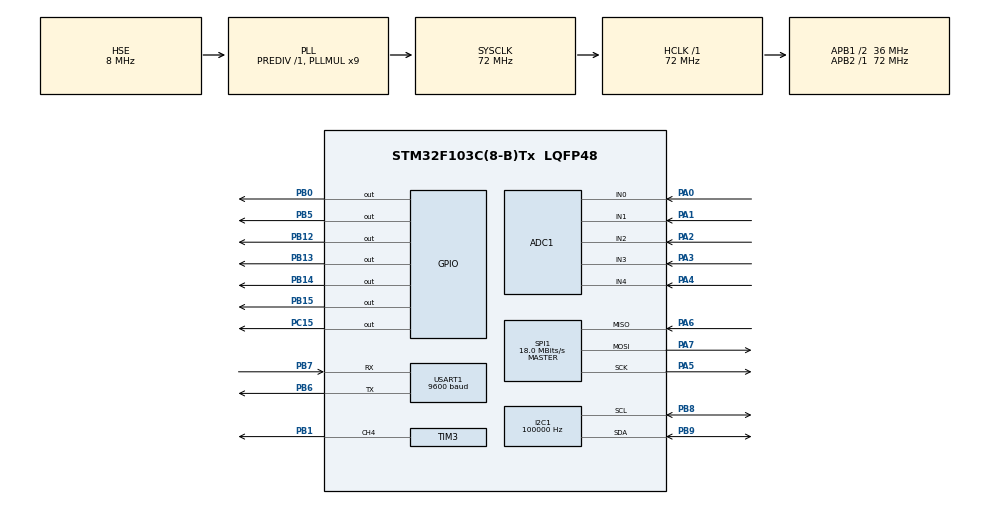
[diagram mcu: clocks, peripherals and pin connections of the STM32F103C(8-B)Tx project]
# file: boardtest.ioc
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ADC1.Channel-12\#ChannelRegularConversion=ADC_CHANNEL_0
ADC1.Channel-13\#ChannelRegularConversion=ADC_CHANNEL_1
ADC1.Channel-14\#ChannelRegularConversion=ADC_CHANNEL_2
ADC1.Channel-15\#ChannelRegularConversion=ADC_CHANNEL_3
ADC1.Channel-16\#ChannelRegularConversion=ADC_CHANNEL_4
ADC1.ContinuousConvMode=ENABLE
ADC1.NbrOfConversion=5
ADC1.NbrOfConversionFlag=1
ADC1.Rank-12\#ChannelRegularConversion=1
ADC1.Rank-13\#ChannelRegularConversion=2
ADC1.Rank-14\#ChannelRegularConversion=3
ADC1.Rank-15\#ChannelRegularConversion=4
ADC1.Rank-16\#ChannelRegularConversion=5
ADC1.SamplingTime-12\#ChannelRegularConversion=ADC_SAMPLETIME_239CYCLES_5
ADC1.SamplingTime-13\#ChannelRegularConversion=ADC_SAMPLETIME_239CYCLES_5
ADC1.SamplingTime-14\#ChannelRegularConversion=ADC_SAMPLETIME_239CYCLES_5
ADC1.SamplingTime-15\#ChannelRegularConversion=ADC_SAMPLETIME_239CYCLES_5
ADC1.SamplingTime-16\#ChannelRegularConversion=ADC_SAMPLETIME_239CYCLES_5
ADC1.master=1
Dma.ADC1.0.Direction=DMA_PERIPH_TO_MEMORY
Dma.ADC1.0.Instance=DMA1_Channel1
Dma.ADC1.0.MemDataAlignment=DMA_MDATAALIGN_HALFWORD
Dma.ADC1.0.MemInc=DMA_MINC_ENABLE
Dma.ADC1.0.Mode=DMA_CIRCULAR
Dma.ADC1.0.PeriphDataAlignment=DMA_PDATAALIGN_HALFWORD
Dma.ADC1.0.PeriphInc=DMA_PINC_DISABLE
Dma.ADC1.0.Priority=DMA_PRIORITY_HIGH
Dma.Request0=ADC1
Dma.Request1=USART1_TX
Dma.USART1_TX.1.Direction=DMA_MEMORY_TO_PERIPH
Dma.USART1_TX.1.Instance=DMA1_Channel4
Dma.USART1_TX.1.MemDataAlignment=DMA_MDATAALIGN_BYTE
Dma.USART1_TX.1.MemInc=DMA_MINC_ENABLE
Dma.USART1_TX.1.Mode=DMA_CIRCULAR
Dma.USART1_TX.1.PeriphDataAlignment=DMA_PDATAALIGN_BYTE
Dma.USART1_TX.1.PeriphInc=DMA_PINC_DISABLE
Dma.USART1_TX.1.Priority=DMA_PRIORITY_MEDIUM
FREERTOS.Tasks01=defaultTask,0,128,StartDefaultTask,Default,NULL,Dynamic,NULL,NULL;myTask_led,-3,128,Task_led,As weak,NULL,Dynamic,NULL,NULL;Task_buzzer,-3,128,myTask_buzzer,As weak,NULL,Dynamic,NULL,NULL;myTask_Date_pac,-3,128,Task_Date_pack,As weak,NULL,Dynamic,NULL,NULL;myTask_adc,-3,128,Task_adc,As weak,NULL,Dynamic,NULL,NULL;myTask_ic_rgb,-3,128,Task_ic_rgb,As weak,NULL,Dynamic,NULL,NULL;myTask_oled_gui,-3,128,Task_oled_gui,As weak,NULL,Dynamic,NULL,NULL;myTask_key,-3,128,Task_key,As weak,NULL,Dynamic,NULL,NULL
FREERTOS.configTOTAL_HEAP_SIZE=10000
I2C1.ClockSpeed=100000
I2C1.I2C_Mode=I2C_Fast
Mcu.Family=STM32F1
Mcu.Name=STM32F103C(8-B)Tx
Mcu.Package=LQFP48
NVIC.DMA1_Channel1_IRQn=true\:5\:0\:false\:false\:true\:true\:false\:true\:true
NVIC.DMA1_Channel4_IRQn=true\:5\:0\:false\:false\:true\:true\:false\:true\:true
NVIC.PriorityGroup=NVIC_PRIORITYGROUP_4
NVIC.USART1_IRQn=true\:5\:0\:false\:false\:true\:true\:true\:true\:true
PA0-WKUP.Signal=ADCx_IN0
PA1.Signal=ADCx_IN1
PA13.Mode=Serial_Wire
PA13.Signal=SYS_JTMS-SWDIO
PA14.Mode=Serial_Wire
PA14.Signal=SYS_JTCK-SWCLK
PA2.Signal=ADCx_IN2
PA3.Signal=ADCx_IN3
PA4.Signal=ADCx_IN4
PA5.Mode=Full_Duplex_Master
PA5.Signal=SPI1_SCK
PA6.Mode=Full_Duplex_Master
PA6.Signal=SPI1_MISO
PA7.Mode=Full_Duplex_Master
PA7.Signal=SPI1_MOSI
PB0.GPIO_Speed=GPIO_SPEED_FREQ_HIGH
PB0.Signal=GPIO_Output
PB1.Signal=S_TIM3_CH4
PB12.Signal=GPIO_Output
PB13.Signal=GPIO_Output
PB14.Signal=GPIO_Output
PB15.Signal=GPIO_Output
PB5.Signal=GPIO_Output
PB6.Mode=Asynchronous
PB6.Signal=USART1_TX
PB7.Mode=Asynchronous
PB7.Signal=USART1_RX
PB8.Mode=I2C
PB8.Signal=I2C1_SCL
PB9.Mode=I2C
PB9.Signal=I2C1_SDA
PC15-OSC32_OUT.GPIO_Speed=GPIO_SPEED_FREQ_HIGH
PC15-OSC32_OUT.Signal=GPIO_Output
PD0-OSC_IN.Mode=HSE-External-Oscillator
PD0-OSC_IN.Signal=RCC_OSC_IN
PD1-OSC_OUT.Mode=HSE-External-Oscillator
PD1-OSC_OUT.Signal=RCC_OSC_OUT
ProjectManager.HeapSize=0x200
ProjectManager.StackSize=0x400
ProjectManager.TargetToolchain=MDK-ARM V5.32
RCC.ADCPresc=RCC_ADCPCLK2_DIV6
RCC.AHBFreq_Value=72000000
RCC.APB1CLKDivider=RCC_HCLK_DIV2
RCC.APB1Freq_Value=36000000
RCC.APB1TimFreq_Value=72000000
RCC.APB2Freq_Value=72000000
RCC.APB2TimFreq_Value=72000000
RCC.HCLKFreq_Value=72000000
RCC.PLLMUL=RCC_PLL_MUL9
RCC.PLLSourceVirtual=RCC_PLLSOURCE_HSE
RCC.SYSCLKFreq_VALUE=72000000
RCC.SYSCLKSource=RCC_SYSCLKSOURCE_PLLCLK
RCC.USBFreq_Value=72000000
SH.ADCx_IN0.0=ADC1_IN0,IN0
SH.ADCx_IN1.0=ADC1_IN1,IN1
SH.ADCx_IN2.0=ADC1_IN2,IN2
SH.ADCx_IN3.0=ADC1_IN3,IN3
SH.ADCx_IN4.0=ADC1_IN4,IN4
SH.S_TIM3_CH4.0=TIM3_CH4,PWM Generation4 CH4
SPI1.BaudRatePrescaler=SPI_BAUDRATEPRESCALER_4
SPI1.CalculateBaudRate=18.0 MBits/s
SPI1.Direction=SPI_DIRECTION_2LINES
SPI1.Mode=SPI_MODE_MASTER
SPI1.VirtualType=VM_MASTER
TIM3.Channel-PWM\ Generation4\ CH4=TIM_CHANNEL_4
TIM3.Period=999
TIM3.Prescaler=1
TIM3.Pulse-PWM\ Generation4\ CH4=500
USART1.BaudRate=9600
USART1.VirtualMode=VM_ASYNC
VP_FREERTOS_VS_CMSIS_V1.Mode=CMSIS_V1
VP_TIM3_VS_ClockSourceINT.Mode=Internal
board=custom

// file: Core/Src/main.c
/* USER CODE BEGIN Header */
/**
  ******************************************************************************
  * @file           : main.c
  * @brief          : Main program body
  ******************************************************************************
  * @attention
  *
  * Copyright (c) 2023 STMicroelectronics.
  * All rights reserved.
  *
  * This software is licensed under terms that can be found in the LICENSE file
  * in the root directory of this software component.
  * If no LICENSE file comes with this software, it is provided AS-IS.
  *
  ******************************************************************************
  */
/* USER CODE END Header */
#include "main.h"
#include "cmsis_os.h"
#include "adc.h"
#include "dma.h"
#include "i2c.h"
#include "spi.h"
#include "tim.h"
#include "usart.h"
#include "gpio.h"

/* USER CODE BEGIN Includes */
#include "oled_iic.h"

/* USER CODE END Includes */

/* USER CODE BEGIN PTD */
//uint8_t ni[4][30]={{0x00,0x00,0x00,0x00,0x00,0x00,0x00,0x00,0x00,0x00,0x00,0x00,0x00,0x00,0x80,0x80,0x00,0x00,0x00,0x00,0x00,0x00,0x00,0x00,0x00,0x00,0x00,0x00,0x00,0x00},
//{0x00,0x1C,0x1C,0x1C,0x1C,0x3C,0xFE,0xFE,0x0E,0x07,0x63,0x20,0x30,0x1C,0x9F,0x8F,0x0F,0xEC,0xEC,0xEC,0x08,0x88,0x88,0x08,0x1C,0xFC,0x38,0x00,0x00,0x00},
//{0x00,0x00,0x00,0x00,0x00,0x80,0xFF,0xFF,0x00,0x00,0x30,0x38,0x1C,0x8F,0x87,0x81,0x80,0xFF,0xFF,0xFF,0x00,0x01,0x07,0x0F,0x1C,0x38,0x70,0x60,0xC0,0x00},
//{0x00,0x00,0x00,0x00,0x00,0x01,0x01,0x01,0x00,0x00,0x00,0x00,0x00,0x00,0x01,0x03,0x03,0x03,0x01,0x00,0x00,0x00,0x00,0x00,0x00,0x00,0x00,0x00,0x00,0x00}};//��
//uint8_t oled_h[6]={0x82,0xFE,0x88,0xF8,0x80,0x00};
//uint8_t oled_null[6]={0x00,0x00,0x00,0x00,0x00,0x00};
//uint8_t oled_e[6]={0x70,0xA8,0xA8,0xB0,0x00,0x00};
//uint8_t oled_l[6]={0x00,0x82,0xFE,0x80,0x00,0x00};
//uint8_t oled_o[6]={0x70,0x88,0x88,0x70,0x00,0x00};
//uint8_t oled_w[6]={0x18,0xE0,0x78,0xE0,0x18,0x00};
//uint8_t oled_r[6]={0x88,0xF8,0x88,0x08,0x00,0x00};
//uint8_t oled_d[6]={0x70,0x88,0x8A,0xFE,0x80,0x00};

int	smoke_value;
uint8_t aTxBuffer[1]={'7'};
/* USER CODE END PTD */

void SystemClock_Config(void);
void MX_FREERTOS_Init(void);

int main(void)
{

  /* MCU Configuration--------------------------------------------------------*/

  /* Reset of all peripherals, Initializes the Flash interface and the Systick. */
  HAL_Init();

  /* Configure the system clock */
  SystemClock_Config();

  /* Initialize all configured peripherals */
  MX_GPIO_Init();
  MX_DMA_Init();
  MX_I2C1_Init();
  MX_USART1_UART_Init();
  MX_TIM3_Init();
  MX_ADC1_Init();
  MX_SPI1_Init();
  /* USER CODE BEGIN 2 */

	HAL_Delay(10);

  /* USER CODE END 2 */

  /* Call init function for freertos objects (in freertos.c) */
  MX_FREERTOS_Init();

  /* Start scheduler */
  osKernelStart();
  /* We should never get here as control is now taken by the scheduler */
  /* Infinite loop */
  while (1)
  {

  }
}

void SystemClock_Config(void)
{
  RCC_OscInitTypeDef RCC_OscInitStruct = {0};
  RCC_ClkInitTypeDef RCC_ClkInitStruct = {0};
  RCC_PeriphCLKInitTypeDef PeriphClkInit = {0};

  /** Initializes the RCC Oscillators according to the specified parameters
  * in the RCC_OscInitTypeDef structure.
  */
  RCC_OscInitStruct.OscillatorType = RCC_OSCILLATORTYPE_HSE;
  RCC_OscInitStruct.HSEState = RCC_HSE_ON;
  RCC_OscInitStruct.HSEPredivValue = RCC_HSE_PREDIV_DIV1;
  RCC_OscInitStruct.HSIState = RCC_HSI_ON;
  RCC_OscInitStruct.PLL.PLLState = RCC_PLL_ON;
  RCC_OscInitStruct.PLL.PLLSource = RCC_PLLSOURCE_HSE;
  RCC_OscInitStruct.PLL.PLLMUL = RCC_PLL_MUL9;
  if (HAL_RCC_OscConfig(&RCC_OscInitStruct) != HAL_OK)
  {
    Error_Handler();
  }

  /** Initializes the CPU, AHB and APB buses clocks
  */
  RCC_ClkInitStruct.ClockType = RCC_CLOCKTYPE_HCLK|RCC_CLOCKTYPE_SYSCLK
                              |RCC_CLOCKTYPE_PCLK1|RCC_CLOCKTYPE_PCLK2;
  RCC_ClkInitStruct.SYSCLKSource = RCC_SYSCLKSOURCE_PLLCLK;
  RCC_ClkInitStruct.AHBCLKDivider = RCC_SYSCLK_DIV1;
  RCC_ClkInitStruct.APB1CLKDivider = RCC_HCLK_DIV2;
  RCC_ClkInitStruct.APB2CLKDivider = RCC_HCLK_DIV1;

  if (HAL_RCC_ClockConfig(&RCC_ClkInitStruct, FLASH_LATENCY_2) != HAL_OK)
  {
    Error_Handler();
  }
  PeriphClkInit.PeriphClockSelection = RCC_PERIPHCLK_ADC;
  PeriphClkInit.AdcClockSelection = RCC_ADCPCLK2_DIV6;
  if (HAL_RCCEx_PeriphCLKConfig(&PeriphClkInit) != HAL_OK)
  {
    Error_Handler();
  }
}

void Error_Handler(void)
{
  __disable_irq();
  while (1)
  {
  }
}

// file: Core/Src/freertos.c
/* USER CODE BEGIN Header */
/**
  ******************************************************************************
  * File Name          : freertos.c
  * Description        : Code for freertos applications
  ******************************************************************************
  * @attention
  *
  * Copyright (c) 2023 STMicroelectronics.
  * All rights reserved.
  *
  * This software is licensed under terms that can be found in the LICENSE file
  * in the root directory of this software component.
  * If no LICENSE file comes with this software, it is provided AS-IS.
  *
  ******************************************************************************
  */
/* USER CODE END Header */

#include "FreeRTOS.h"
#include "task.h"
#include "main.h"
#include "cmsis_os.h"

osThreadId defaultTaskHandle;
osThreadId myTask_ledHandle;
osThreadId Task_buzzerHandle;
osThreadId myTask_Date_pacHandle;
osThreadId myTask_adcHandle;
osThreadId myTask_ic_rgbHandle;
osThreadId myTask_oled_guiHandle;
osThreadId myTask_keyHandle;

void StartDefaultTask(void const * argument);
void Task_led(void const * argument);
void myTask_buzzer(void const * argument);
void Task_Date_pack(void const * argument);
void Task_adc(void const * argument);
void Task_ic_rgb(void const * argument);
void Task_oled_gui(void const * argument);
void Task_key(void const * argument);

void MX_FREERTOS_Init(void); /* (MISRA C 2004 rule 8.1) */

/* GetIdleTaskMemory prototype (linked to static allocation support) */
void vApplicationGetIdleTaskMemory( StaticTask_t **ppxIdleTaskTCBBuffer, StackType_t **ppxIdleTaskStackBuffer, uint32_t *pulIdleTaskStackSize );

/* USER CODE BEGIN GET_IDLE_TASK_MEMORY */
static StaticTask_t xIdleTaskTCBBuffer;
static StackType_t xIdleStack[configMINIMAL_STACK_SIZE];

void vApplicationGetIdleTaskMemory( StaticTask_t **ppxIdleTaskTCBBuffer, StackType_t **ppxIdleTaskStackBuffer, uint32_t *pulIdleTaskStackSize )
{
  *ppxIdleTaskTCBBuffer = &xIdleTaskTCBBuffer;
  *ppxIdleTaskStackBuffer = &xIdleStack[0];
  *pulIdleTaskStackSize = configMINIMAL_STACK_SIZE;
  /* place for user code */
}
/* USER CODE END GET_IDLE_TASK_MEMORY */

void MX_FREERTOS_Init(void) {

  /* Create the thread(s) */
  /* definition and creation of defaultTask */
  osThreadDef(defaultTask, StartDefaultTask, osPriorityNormal, 0, 128);
  defaultTaskHandle = osThreadCreate(osThread(defaultTask), NULL);

  /* definition and creation of myTask_led */
  osThreadDef(myTask_led, Task_led, osPriorityIdle, 0, 128);
  myTask_ledHandle = osThreadCreate(osThread(myTask_led), NULL);

  /* definition and creation of Task_buzzer */
  osThreadDef(Task_buzzer, myTask_buzzer, osPriorityIdle, 0, 128);
  Task_buzzerHandle = osThreadCreate(osThread(Task_buzzer), NULL);

  /* definition and creation of myTask_Date_pac */
  osThreadDef(myTask_Date_pac, Task_Date_pack, osPriorityIdle, 0, 128);
  myTask_Date_pacHandle = osThreadCreate(osThread(myTask_Date_pac), NULL);

  /* definition and creation of myTask_adc */
  osThreadDef(myTask_adc, Task_adc, osPriorityIdle, 0, 128);
  myTask_adcHandle = osThreadCreate(osThread(myTask_adc), NULL);

  /* definition and creation of myTask_ic_rgb */
  osThreadDef(myTask_ic_rgb, Task_ic_rgb, osPriorityIdle, 0, 128);
  myTask_ic_rgbHandle = osThreadCreate(osThread(myTask_ic_rgb), NULL);

  /* definition and creation of myTask_oled_gui */
  osThreadDef(myTask_oled_gui, Task_oled_gui, osPriorityIdle, 0, 128);
  myTask_oled_guiHandle = osThreadCreate(osThread(myTask_oled_gui), NULL);

  /* definition and creation of myTask_key */
  osThreadDef(myTask_key, Task_key, osPriorityIdle, 0, 128);
  myTask_keyHandle = osThreadCreate(osThread(myTask_key), NULL);

}

void StartDefaultTask(void const * argument)
{
  for(;;)
  {
    osDelay(1);
  }
}

__weak void Task_led(void const * argument)
{
  for(;;)
  {
    osDelay(1);
  }
}

__weak void myTask_buzzer(void const * argument)
{
  for(;;)
  {
    osDelay(1);
  }
}

__weak void Task_Date_pack(void const * argument)
{
  for(;;)
  {
    osDelay(1);
  }
}

__weak void Task_adc(void const * argument)
{
  for(;;)
  {
    osDelay(1);
  }
}

__weak void Task_ic_rgb(void const * argument)
{
  for(;;)
  {
    osDelay(1);
  }
}

__weak void Task_oled_gui(void const * argument)
{
  for(;;)
  {
    osDelay(1);
  }
}

__weak void Task_key(void const * argument)
{
  for(;;)
  {
    osDelay(1);
  }
}
